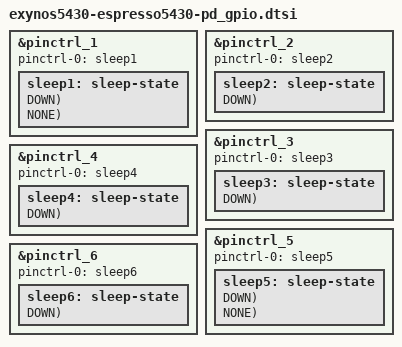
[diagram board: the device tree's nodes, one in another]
/*
 * SAMSUNG ESPRESSO5430 board device tree source
 *
 * Copyright (c) 2014 Samsung Electronics Co., Ltd.
 *		http://www.samsung.com
 *
 * This program is free software; you can redistribute it and/or modify
 * it under the terms of the GNU General Public License version 2 as
 * published by the Free Software Foundation.
*/

#define PIN_CON_INPUT		0
#define PIN_CON_OUTPUT		1

#define PIN_PULL_NONE		0
#define PIN_PULL_DOWN		1
#define PIN_PULL_UP		3

#define PIN_PDN_OUT0		0
#define PIN_PDN_OUT1		1
#define PIN_PDN_INPUT		2
#define PIN_PDN_PREV		3

#define PIN_IN(_pin, _pull)			\
	_pin {						\
		samsung,pins = #_pin;			\
		samsung,pin-function = <0>;		\
		samsung,pin-pud = <PIN_PULL_ ##_pull>;	\
	}

#define PIN_OUT(_pin)				\
	_pin {						\
		samsung,pins = #_pin;			\
		samsung,pin-function = <1>;		\
		samsung,pin-pud = <0>;			\
	}

#define PIN_OUT_SET(_pin, _val)			\
	_pin {						\
		samsung,pins = #_pin;			\
		samsung,pin-function = <1>;		\
		samsung,pin-pud = <0>;			\
		samsung,pin-val	= <_val>;		\
	}

#define PIN_SLP(_pin, _mode, _pull)				\
	_pin {							\
		samsung,pins = #_pin;				\
		samsung,pin-con-pdn = <PIN_PDN_ ##_mode>;	\
		samsung,pin-pud-pdn = <PIN_PULL_ ##_pull>;	\
	}
/*
&pinctrl_0 {
	pinctrl-names = "sleep";
	pinctrl-0 = <&sleep0>;
	sleep0: sleep-state {
		PIN_IN(gpa0-0, DOWN);
		PIN_IN(gpa0-1, DOWN);
		PIN_IN(gpa0-2, DOWN);
		PIN_IN(gpa0-3, DOWN);
		PIN_IN(gpa0-4, DOWN);
		PIN_OUT(gpa0-5, DOWN);
		PIN_IN(gpa0-6, DOWN);
		PIN_IN(gpa0-7, DOWN);

		PIN_IN(gpa1-0, DOWN);
		PIN_IN(gpa1-1, DOWN);
		PIN_IN(gpa1-2, DOWN);
		PIN_IN(gpa1-3, DOWN);
		PIN_IN(gpa1-4, DOWN);
		PIN_IN(gpa1-5, DOWN);
		PIN_IN(gpa1-6, DOWN);
		PIN_IN(gpa1-7, DOWN);

		PIN_IN(gpa2-0, DOWN);
		PIN_IN(gpa2-1, DOWN);
		PIN_IN(gpa2-2, DOWN);
		PIN_IN(gpa2-3, DOWN);
		PIN_IN(gpa2-4, DOWN);
		PIN_IN(gpa2-5, DOWN);
		PIN_IN(gpa2-6, DOWN);
		PIN_IN(gpa2-7, DOWN);

		PIN_IN(gpa3-0, DOWN);
		PIN_IN(gpa3-1, DOWN);
		PIN_IN(gpa3-2, DOWN);
		PIN_IN(gpa3-3, DOWN);
		PIN_IN(gpa3-4, DOWN);
		PIN_IN(gpa3-5, DOWN);
		PIN_IN(gpa3-6, DOWN);
		PIN_IN(gpa3-7, DOWN);
	};
};
*/
&pinctrl_1 {
	pinctrl-names = "sleep";
	pinctrl-0 = <&sleep1>;
	sleep1: sleep-state {
		PIN_SLP(gpz0-0, INPUT, DOWN);	/* MM_I2S_CLK */
		PIN_SLP(gpz0-1, INPUT, DOWN);	/* NC */
		PIN_SLP(gpz0-2, INPUT, DOWN);	/* MM_I2S_SYNC */
		PIN_SLP(gpz0-3, INPUT, DOWN);	/* MM_I2S_DI */
		PIN_SLP(gpz0-4, INPUT, DOWN);	/* MM_I2S_DO */
		PIN_SLP(gpz0-5, INPUT, DOWN);	/* NC */
		PIN_SLP(gpz0-6, INPUT, DOWN);	/* NC */

		PIN_SLP(gpz1-0, INPUT, DOWN);	/* BT_UART_TXD */
		PIN_SLP(gpz1-1, INPUT, NONE);	/* BT_UART_RXD */
		PIN_SLP(gpz1-2, INPUT, DOWN);	/* BT_UART_CTS */
		PIN_SLP(gpz1-3, INPUT, DOWN);	/* BT_UART_RTS */
	};
};

&pinctrl_2 {
	pinctrl-names = "sleep";
	pinctrl-0 = <&sleep2>;
	sleep2: sleep-state {
		PIN_SLP(gpv6-0, INPUT, DOWN);
		PIN_SLP(gpv6-1, INPUT, DOWN);
		PIN_SLP(gpv6-2, INPUT, DOWN);
	};
};

&pinctrl_3 {
	pinctrl-names = "sleep";
	pinctrl-0 = <&sleep3>;
	sleep3: sleep-state {
		PIN_SLP(gph1-0, INPUT, DOWN);
		PIN_SLP(gph1-1, INPUT, DOWN);
		PIN_SLP(gph1-2, INPUT, DOWN);
		PIN_SLP(gph1-3, INPUT, DOWN);

		PIN_SLP(gpr4-0, INPUT, DOWN);
		PIN_SLP(gpr4-1, INPUT, DOWN);
		PIN_SLP(gpr4-2, INPUT, DOWN);
		PIN_SLP(gpr4-3, INPUT, DOWN);
		PIN_SLP(gpr4-4, INPUT, DOWN);
		PIN_SLP(gpr4-5, INPUT, DOWN);
		PIN_SLP(gpr4-6, INPUT, DOWN);

		PIN_SLP(gpr0-0, INPUT, DOWN);
		PIN_SLP(gpr0-1, INPUT, DOWN);
		PIN_SLP(gpr0-2, INPUT, DOWN);
		PIN_SLP(gpr0-3, INPUT, DOWN);
		PIN_SLP(gpr0-4, INPUT, DOWN);

		PIN_SLP(gpr1-0, INPUT, DOWN);
		PIN_SLP(gpr1-1, INPUT, DOWN);
		PIN_SLP(gpr1-2, INPUT, DOWN);
		PIN_SLP(gpr1-3, INPUT, DOWN);
		PIN_SLP(gpr1-4, INPUT, DOWN);
		PIN_SLP(gpr1-5, INPUT, DOWN);
		PIN_SLP(gpr1-6, INPUT, DOWN);
		PIN_SLP(gpr1-7, INPUT, DOWN);

		PIN_SLP(gpr2-0, INPUT, DOWN);
		PIN_SLP(gpr2-1, INPUT, DOWN);

		PIN_SLP(gpr3-0, INPUT, DOWN);
		PIN_SLP(gpr3-1, INPUT, DOWN);
		PIN_SLP(gpr3-2, INPUT, DOWN);
		PIN_SLP(gpr3-3, INPUT, DOWN);
		PIN_SLP(gpr3-4, INPUT, DOWN);
		PIN_SLP(gpr3-5, INPUT, DOWN);
		PIN_SLP(gpr3-6, INPUT, DOWN);
		PIN_SLP(gpr3-7, INPUT, DOWN);
	};
};

&pinctrl_4 {
	pinctrl-names = "sleep";
	pinctrl-0 = <&sleep4>;
	sleep4: sleep-state {
		PIN_SLP(gpj0-0, INPUT, DOWN);
		PIN_SLP(gpj0-1, INPUT, DOWN);
		PIN_SLP(gpj0-2, INPUT, DOWN);
	};
};

&pinctrl_5 {
	pinctrl-names = "sleep";
	pinctrl-0 = <&sleep5>;
	sleep5: sleep-state {
		PIN_SLP(gpv7-0, INPUT, DOWN);
		PIN_SLP(gpv7-1, INPUT, DOWN);
		PIN_SLP(gpv7-2, INPUT, DOWN);
		PIN_SLP(gpv7-3, INPUT, DOWN);
		PIN_SLP(gpv7-4, INPUT, DOWN);

		PIN_SLP(gpb0-0, INPUT, DOWN);
		PIN_SLP(gpb0-1, INPUT, DOWN);
		PIN_SLP(gpb0-2, INPUT, DOWN);
		PIN_SLP(gpb0-3, INPUT, DOWN);
		PIN_SLP(gpb0-4, INPUT, DOWN);

		PIN_SLP(gpc0-0, INPUT, DOWN);
		PIN_SLP(gpc0-1, INPUT, DOWN);
		PIN_SLP(gpc0-2, INPUT, DOWN);
		PIN_SLP(gpc0-3, INPUT, DOWN);
		PIN_SLP(gpc0-4, INPUT, DOWN);
		PIN_SLP(gpc0-5, INPUT, DOWN);
		PIN_SLP(gpc0-6, INPUT, DOWN);
		PIN_SLP(gpc0-7, INPUT, DOWN);

		PIN_SLP(gpc1-0, INPUT, DOWN);
		PIN_SLP(gpc1-1, INPUT, DOWN);

		PIN_SLP(gpc2-0, INPUT, DOWN);
		PIN_SLP(gpc2-1, INPUT, DOWN);
		PIN_SLP(gpc2-2, INPUT, DOWN);
		PIN_SLP(gpc2-3, INPUT, DOWN);
		PIN_SLP(gpc2-4, INPUT, DOWN);
		PIN_SLP(gpc2-5, INPUT, DOWN);

		PIN_SLP(gpc3-0, INPUT, DOWN);
		PIN_SLP(gpc3-1, INPUT, DOWN);
		PIN_SLP(gpc3-2, INPUT, DOWN);
		PIN_SLP(gpc3-3, INPUT, DOWN);
		PIN_SLP(gpc3-4, INPUT, DOWN);
		PIN_SLP(gpc3-5, INPUT, DOWN);
		PIN_SLP(gpc3-6, INPUT, DOWN);
		PIN_SLP(gpc3-7, INPUT, DOWN);

		PIN_SLP(gpg0-0, INPUT, DOWN);
		PIN_SLP(gpg0-1, INPUT, DOWN);

		PIN_SLP(gpd0-0, INPUT, DOWN);
		PIN_SLP(gpd0-1, INPUT, DOWN);
		PIN_SLP(gpd0-2, INPUT, DOWN);
		PIN_SLP(gpd0-3, INPUT, DOWN);

		PIN_SLP(gpd1-0, INPUT, DOWN);
		PIN_SLP(gpd1-1, INPUT, DOWN);
		PIN_SLP(gpd1-2, INPUT, DOWN);
		PIN_SLP(gpd1-3, INPUT, DOWN);
		PIN_SLP(gpd1-4, INPUT, DOWN);
		PIN_SLP(gpd1-5, INPUT, DOWN);

		PIN_SLP(gpd2-0, INPUT, DOWN);
		PIN_SLP(gpd2-1, INPUT, DOWN);
		PIN_SLP(gpd2-2, INPUT, DOWN);
		PIN_SLP(gpd2-3, INPUT, DOWN);
		PIN_SLP(gpd2-4, INPUT, DOWN);
		PIN_SLP(gpd2-5, INPUT, DOWN);
		PIN_SLP(gpd2-6, INPUT, DOWN);
		PIN_SLP(gpd2-7, INPUT, DOWN);

		PIN_SLP(gpd4-0, INPUT, DOWN);
		PIN_SLP(gpd4-1, INPUT, DOWN);
		PIN_SLP(gpd4-2, INPUT, DOWN);
		PIN_SLP(gpd4-3, INPUT, DOWN);
		PIN_SLP(gpd4-4, INPUT, DOWN);

		PIN_SLP(gpd5-0, INPUT, DOWN);
		PIN_SLP(gpd5-1, INPUT, DOWN);
		PIN_SLP(gpd5-2, INPUT, DOWN);
		PIN_SLP(gpd5-3, INPUT, DOWN);

		PIN_SLP(gpd8-0, INPUT, DOWN);
		PIN_SLP(gpd8-1, INPUT, DOWN);

		PIN_SLP(gpd6-0, INPUT, DOWN);
		PIN_SLP(gpd6-1, INPUT, DOWN);
		PIN_SLP(gpd6-2, INPUT, DOWN);
		PIN_SLP(gpd6-3, INPUT, DOWN);
		PIN_SLP(gpd6-4, INPUT, DOWN);
		PIN_SLP(gpd6-5, INPUT, DOWN);

		PIN_SLP(gpd7-0, INPUT, DOWN);
		PIN_SLP(gpd7-1, INPUT, DOWN);
		PIN_SLP(gpd7-2, INPUT, DOWN);

		PIN_SLP(gpf0-0, INPUT, DOWN);
		PIN_SLP(gpf0-1, INPUT, DOWN);
		PIN_SLP(gpf0-2, INPUT, DOWN);
		PIN_SLP(gpf0-3, INPUT, DOWN);
		PIN_SLP(gpf0-4, INPUT, DOWN);
		PIN_SLP(gpf0-5, INPUT, DOWN);
		PIN_SLP(gpf0-6, INPUT, DOWN);
		PIN_SLP(gpf0-7, INPUT, DOWN);

		PIN_SLP(gpf1-0, INPUT, DOWN);
		PIN_SLP(gpf1-1, INPUT, DOWN);
		PIN_SLP(gpf1-2, INPUT, DOWN);
		PIN_SLP(gpf1-3, INPUT, DOWN);
		PIN_SLP(gpf1-4, INPUT, DOWN);
		PIN_SLP(gpf1-5, INPUT, DOWN);
		PIN_SLP(gpf1-6, INPUT, DOWN);
		PIN_SLP(gpf1-7, INPUT, DOWN);

		PIN_SLP(gpf2-0, INPUT, DOWN);
		PIN_SLP(gpf2-1, INPUT, DOWN);
		PIN_SLP(gpf2-2, INPUT, DOWN);
		PIN_SLP(gpf2-3, INPUT, DOWN);

		PIN_SLP(gpf3-0, INPUT, DOWN);
		PIN_SLP(gpf3-1, INPUT, DOWN);
		PIN_SLP(gpf3-2, INPUT, DOWN);
		PIN_SLP(gpf3-3, INPUT, DOWN);
		PIN_SLP(gpf3-4, INPUT, DOWN);
		PIN_SLP(gpf3-5, INPUT, DOWN);

		PIN_SLP(gpf4-0, INPUT, DOWN);
		PIN_SLP(gpf4-1, INPUT, DOWN);
		PIN_SLP(gpf4-2, INPUT, DOWN);
		PIN_SLP(gpf4-3, INPUT, DOWN);
		PIN_SLP(gpf4-4, INPUT, DOWN);
		PIN_SLP(gpf4-5, INPUT, DOWN);
		PIN_SLP(gpf4-6, INPUT, DOWN);
		PIN_SLP(gpf4-7, INPUT, DOWN);

		PIN_SLP(gpf5-0, INPUT, DOWN);
		PIN_SLP(gpf5-1, INPUT, DOWN);
		PIN_SLP(gpf5-2, INPUT, DOWN);
		PIN_SLP(gpf5-3, INPUT, DOWN);
		PIN_SLP(gpf5-4, INPUT, DOWN);
		PIN_SLP(gpf5-5, INPUT, DOWN);
		PIN_SLP(gpf5-6, INPUT, DOWN);
		PIN_SLP(gpf5-7, INPUT, DOWN);

		PIN_SLP(gpg1-0, INPUT, DOWN);
		PIN_SLP(gpg1-1, INPUT, DOWN);
		PIN_SLP(gpg1-2, INPUT, DOWN);
		PIN_SLP(gpg1-3, INPUT, DOWN);
		PIN_SLP(gpg1-4, INPUT, DOWN);

		PIN_SLP(gpg2-0, INPUT, DOWN);
		PIN_SLP(gpg2-1, INPUT, DOWN);
		PIN_SLP(gpg2-2, INPUT, DOWN);
		PIN_SLP(gpg2-3, INPUT, DOWN);
		PIN_SLP(gpg2-4, INPUT, DOWN);

		PIN_SLP(gpg3-0, INPUT, DOWN);
		PIN_SLP(gpg3-1, INPUT, DOWN);
		PIN_SLP(gpg3-2, INPUT, DOWN);
		PIN_SLP(gpg3-3, INPUT, DOWN);
		PIN_SLP(gpg3-4, OUT1, NONE);
		PIN_SLP(gpg3-5, OUT1, NONE);
		PIN_SLP(gpg3-6, INPUT, DOWN);
		PIN_SLP(gpg3-7, INPUT, DOWN);
	};
};

&pinctrl_6 {
	pinctrl-names = "sleep";
	pinctrl-0 = <&sleep6>;
	sleep6: sleep-state {
		PIN_SLP(gpj1-0, INPUT, DOWN);
		PIN_SLP(gpj1-1, INPUT, DOWN);
		PIN_SLP(gpj1-2, INPUT, DOWN);
	};
};
